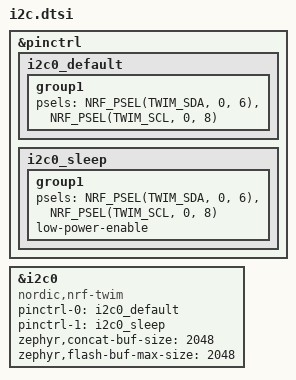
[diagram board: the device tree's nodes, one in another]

&pinctrl {
  i2c0_default: i2c0_default {
    group1 {
      psels = <NRF_PSEL(TWIM_SDA, 0, 6)>
        , <NRF_PSEL(TWIM_SCL, 0, 8)>;
    };
  };

  i2c0_sleep: i2c0_sleep {
    group1 {
      psels = <NRF_PSEL(TWIM_SDA, 0, 6)>
        , <NRF_PSEL(TWIM_SCL, 0, 8)>;
      low-power-enable;
    };
  };
};

&i2c0 {
  compatible = "nordic,nrf-twim";

  status = "okay";

  pinctrl-0 = <&i2c0_default>;
  pinctrl-1 = <&i2c0_sleep>;
  pinctrl-names = "default", "sleep";
  zephyr,concat-buf-size = <2048>;
  zephyr,flash-buf-max-size = <2048>;
};
